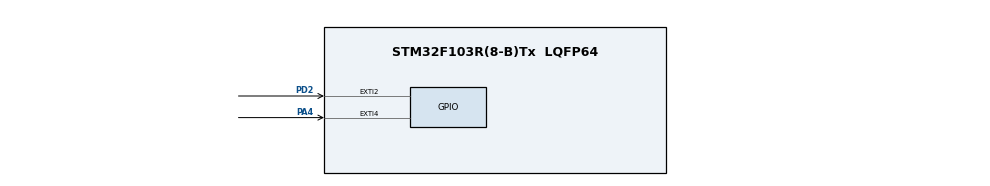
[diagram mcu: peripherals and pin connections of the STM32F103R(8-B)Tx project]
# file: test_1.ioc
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Mcu.Family=STM32F1
Mcu.Name=STM32F103R(8-B)Tx
Mcu.Package=LQFP64
NVIC.EXTI2_IRQn=true\:0\:0\:false\:false\:true\:true\:true\:true
NVIC.EXTI4_IRQn=true\:0\:0\:false\:false\:true\:true\:true\:true
NVIC.PriorityGroup=NVIC_PRIORITYGROUP_4
NVIC.TIM3_IRQn=true\:0\:0\:false\:false\:true\:true\:true\:true
PA4.Signal=GPXTI4
PD2.Signal=GPXTI2
ProjectManager.HeapSize=0x200
ProjectManager.StackSize=0x400
ProjectManager.TargetToolchain=STM32CubeIDE
RCC.APB1Freq_Value=8000000
RCC.APB2Freq_Value=8000000
TIM3.AutoReloadPreload=TIM_AUTORELOAD_PRELOAD_ENABLE
TIM3.Period=999
TIM3.Prescaler=71
VP_TIM3_VS_ClockSourceINT.Mode=Internal
board=custom

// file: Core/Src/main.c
/* USER CODE BEGIN Header */
/**
  ******************************************************************************
  * @file           : main.c
  * @brief          : Main program body
  ******************************************************************************
  * @attention
  *
  * Copyright (c) 2023 STMicroelectronics.
  * All rights reserved.
  *
  * This software is licensed under terms that can be found in the LICENSE file
  * in the root directory of this software component.
  * If no LICENSE file comes with this software, it is provided AS-IS.
  *
  ******************************************************************************
  */
/* USER CODE END Header */
#include "main.h"

TIM_HandleTypeDef htim3;

/* USER CODE BEGIN PV */
int count = 0;
/* USER CODE END PV */

void SystemClock_Config(void);
static void MX_GPIO_Init(void);
static void MX_TIM3_Init(void);

int main(void)
{
  /* USER CODE BEGIN 1 */
	HAL_TIM_Base_Start_IT(&htim3);
  /* USER CODE END 1 */

  /* MCU Configuration--------------------------------------------------------*/

  /* Reset of all peripherals, Initializes the Flash interface and the Systick. */
  HAL_Init();

  /* Configure the system clock */
  SystemClock_Config();

  /* Initialize all configured peripherals */
  MX_GPIO_Init();
  MX_TIM3_Init();

  /* Infinite loop */
  while (1)
  {

  }
}

void SystemClock_Config(void)
{
  RCC_OscInitTypeDef RCC_OscInitStruct = {0};
  RCC_ClkInitTypeDef RCC_ClkInitStruct = {0};

  /** Initializes the RCC Oscillators according to the specified parameters
  * in the RCC_OscInitTypeDef structure.
  */
  RCC_OscInitStruct.OscillatorType = RCC_OSCILLATORTYPE_HSI;
  RCC_OscInitStruct.HSIState = RCC_HSI_ON;
  RCC_OscInitStruct.HSICalibrationValue = RCC_HSICALIBRATION_DEFAULT;
  RCC_OscInitStruct.PLL.PLLState = RCC_PLL_NONE;
  if (HAL_RCC_OscConfig(&RCC_OscInitStruct) != HAL_OK)
  {
    Error_Handler();
  }

  /** Initializes the CPU, AHB and APB buses clocks
  */
  RCC_ClkInitStruct.ClockType = RCC_CLOCKTYPE_HCLK|RCC_CLOCKTYPE_SYSCLK
                              |RCC_CLOCKTYPE_PCLK1|RCC_CLOCKTYPE_PCLK2;
  RCC_ClkInitStruct.SYSCLKSource = RCC_SYSCLKSOURCE_HSI;
  RCC_ClkInitStruct.AHBCLKDivider = RCC_SYSCLK_DIV1;
  RCC_ClkInitStruct.APB1CLKDivider = RCC_HCLK_DIV1;
  RCC_ClkInitStruct.APB2CLKDivider = RCC_HCLK_DIV1;

  if (HAL_RCC_ClockConfig(&RCC_ClkInitStruct, FLASH_LATENCY_0) != HAL_OK)
  {
    Error_Handler();
  }
}

static void MX_TIM3_Init(void)
{

  TIM_ClockConfigTypeDef sClockSourceConfig = {0};
  TIM_MasterConfigTypeDef sMasterConfig = {0};

  htim3.Instance = TIM3;
  htim3.Init.Prescaler = 71;
  htim3.Init.CounterMode = TIM_COUNTERMODE_UP;
  htim3.Init.Period = 999;
  htim3.Init.ClockDivision = TIM_CLOCKDIVISION_DIV1;
  htim3.Init.AutoReloadPreload = TIM_AUTORELOAD_PRELOAD_ENABLE;
  if (HAL_TIM_Base_Init(&htim3) != HAL_OK)
  {
    Error_Handler();
  }
  sClockSourceConfig.ClockSource = TIM_CLOCKSOURCE_INTERNAL;
  if (HAL_TIM_ConfigClockSource(&htim3, &sClockSourceConfig) != HAL_OK)
  {
    Error_Handler();
  }
  sMasterConfig.MasterOutputTrigger = TIM_TRGO_RESET;
  sMasterConfig.MasterSlaveMode = TIM_MASTERSLAVEMODE_DISABLE;
  if (HAL_TIMEx_MasterConfigSynchronization(&htim3, &sMasterConfig) != HAL_OK)
  {
    Error_Handler();
  }

}

static void MX_GPIO_Init(void)
{
  GPIO_InitTypeDef GPIO_InitStruct = {0};

  /* GPIO Ports Clock Enable */
  __HAL_RCC_GPIOA_CLK_ENABLE();
  __HAL_RCC_GPIOD_CLK_ENABLE();

  /*Configure GPIO pin : PA4 */
  GPIO_InitStruct.Pin = GPIO_PIN_4;
  GPIO_InitStruct.Mode = GPIO_MODE_IT_RISING;
  GPIO_InitStruct.Pull = GPIO_NOPULL;
  HAL_GPIO_Init(GPIOA, &GPIO_InitStruct);

  /*Configure GPIO pin : PD2 */
  GPIO_InitStruct.Pin = GPIO_PIN_2;
  GPIO_InitStruct.Mode = GPIO_MODE_IT_RISING;
  GPIO_InitStruct.Pull = GPIO_NOPULL;
  HAL_GPIO_Init(GPIOD, &GPIO_InitStruct);

  /* EXTI interrupt init*/
  HAL_NVIC_SetPriority(EXTI2_IRQn, 0, 0);
  HAL_NVIC_EnableIRQ(EXTI2_IRQn);

  HAL_NVIC_SetPriority(EXTI4_IRQn, 0, 0);
  HAL_NVIC_EnableIRQ(EXTI4_IRQn);

}

/* USER CODE BEGIN 4 */
void HAL_TIM_PeriodElapsedCallback(TIM_HandleTypeDef *htim)
{
	if(count == 0){
		HAL_GPIO_WritePin(GPIOB, GPIO_PIN_15, PGIO_RESET);
		HAL_GPIO_WritePin(GPIOB, GPIO_PIN_13, PGIO_RESET);
	}
	else if(count == 500){
		HAL_GPIO_WritePin(GPIOB,GPIO_PIN_15, GPIO_SET);
	}
	else if(count == 1000){
			HAL_GPIO_WritePin(GPIOB,GPIO_PIN_15, GPIO_RESET);
		}
	else if(count == 1500){
			HAL_GPIO_WritePin(GPIOB,GPIO_PIN_15, GPIO_SET);
			HAL_GPIO_WritePin(GPIOB,GPIO_PIN_13, GPIO_SET);
		}
	else if(count == 2000){
			HAL_GPIO_WritePin(GPIOB,GPIO_PIN_15, GPIO_RESET);
		}
	else if(count == 2500){
			HAL_GPIO_WritePin(GPIOB,GPIO_PIN_15, GPIO_SET);
		}
	else if(++count == 3000){
			count = 0;
		}
}

/* USER CODE END 4 */

void Error_Handler(void)
{
  __disable_irq();
  while (1)
  {
  }
}
